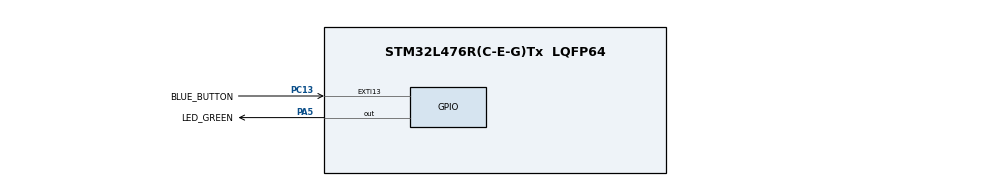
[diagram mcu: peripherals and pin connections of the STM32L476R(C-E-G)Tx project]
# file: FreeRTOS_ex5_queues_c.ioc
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FREERTOS.Queues01=Queue1,8,Data,0,Dynamic,NULL,NULL
FREERTOS.Tasks01=Sender1,24,256,StartSender1,Default,NULL,Dynamic,NULL,NULL;Receive,24,256,StartReceive,Default,NULL,Dynamic,NULL,NULL;Sender2,24,256,StartSender2,Default,NULL,Dynamic,NULL,NULL
FREERTOS.configTOTAL_HEAP_SIZE=4000
FREERTOS.configUSE_NEWLIB_REENTRANT=1
Mcu.Family=STM32L4
Mcu.Name=STM32L476R(C-E-G)Tx
Mcu.Package=LQFP64
NVIC.EXTI15_10_IRQn=true\:5\:0\:true\:false\:true\:false\:true\:true\:true
NVIC.PriorityGroup=NVIC_PRIORITYGROUP_4
NVIC.TIM6_DAC_IRQn=true\:15\:0\:false\:false\:true\:false\:false\:true\:true
NVIC.TimeBase=TIM6_DAC_IRQn
NVIC.TimeBaseIP=TIM6
PA13\ (JTMS-SWDIO).Mode=Trace_Asynchronous_SW
PA13\ (JTMS-SWDIO).Signal=SYS_JTMS-SWDIO
PA14\ (JTCK-SWCLK).Mode=Trace_Asynchronous_SW
PA14\ (JTCK-SWCLK).Signal=SYS_JTCK-SWCLK
PA5.GPIO_Label=LED_GREEN
PA5.Signal=GPIO_Output
PB3\ (JTDO-TRACESWO).Mode=Trace_Asynchronous_SW
PB3\ (JTDO-TRACESWO).Signal=SYS_JTDO-SWO
PC13.GPIO_Label=BLUE_BUTTON
PC13.Signal=GPXTI13
ProjectManager.HeapSize=0x200
ProjectManager.StackSize=0x400
ProjectManager.TargetToolchain=STM32CubeIDE
RCC.HSE_VALUE=8000000
RCC.HSI_VALUE=16000000
RCC.LSE_VALUE=32768
RCC.MSI_VALUE=4000000
RCC.VCOOutputFreq_Value=32000000
VP_FREERTOS_VS_CMSIS_V2.Mode=CMSIS_V2
VP_SYS_VS_tim6.Mode=TIM6
board=custom

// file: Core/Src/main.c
/* USER CODE BEGIN Header */
/**
  ******************************************************************************
  * @file           : main.c
  * @brief          : Main program body
  ******************************************************************************
  * @attention
  *
  * Copyright (c) 2024 STMicroelectronics.
  * All rights reserved.
  *
  * This software is licensed under terms that can be found in the LICENSE file
  * in the root directory of this software component.
  * If no LICENSE file comes with this software, it is provided AS-IS.
  *
  ******************************************************************************
  */
/* USER CODE END Header */
#include "main.h"
#include "cmsis_os.h"

/* USER CODE BEGIN Includes */
#include "stm32l4xx_hal.h"

/* USER CODE END Includes */

/* Definitions for Sender1 */
osThreadId_t Sender1Handle;
const osThreadAttr_t Sender1_attributes = {
  .name = "Sender1",
  .stack_size = 256 * 4,
  .priority = (osPriority_t) osPriorityNormal,
};
/* Definitions for Receive */
osThreadId_t ReceiveHandle;
const osThreadAttr_t Receive_attributes = {
  .name = "Receive",
  .stack_size = 256 * 4,
  .priority = (osPriority_t) osPriorityNormal,
};
/* Definitions for Sender2 */
osThreadId_t Sender2Handle;
const osThreadAttr_t Sender2_attributes = {
  .name = "Sender2",
  .stack_size = 256 * 4,
  .priority = (osPriority_t) osPriorityNormal,
};
/* Definitions for Queue1 */
osMessageQueueId_t Queue1Handle;
const osMessageQueueAttr_t Queue1_attributes = {
  .name = "Queue1"
};
/* USER CODE BEGIN PV */
osStatus_t r_state;
typedef struct
{
	uint16_t value;
	uint8_t source;
} Data;
Data DataToSend1 = {'a', 1};
Data DataToSend2 = {'b', 2};

/* USER CODE END PV */

void SystemClock_Config(void);
static void MX_GPIO_Init(void);
void StartSender1(void *argument);
void StartReceive(void *argument);
void StartSender2(void *argument);

/* USER CODE BEGIN PFP */
void task_action(char message);
/* USER CODE END PFP */

int main(void)
{

  /* MCU Configuration--------------------------------------------------------*/

  /* Reset of all peripherals, Initializes the Flash interface and the Systick. */
  HAL_Init();

  /* Configure the system clock */
  SystemClock_Config();

  /* Initialize all configured peripherals */
  MX_GPIO_Init();

  /* Init scheduler */
  osKernelInitialize();

  /* Create the queue(s) */
  /* creation of Queue1 */
  Queue1Handle = osMessageQueueNew (8, sizeof(Data), &Queue1_attributes);

  /* Create the thread(s) */
  /* creation of Sender1 */
  Sender1Handle = osThreadNew(StartSender1, NULL, &Sender1_attributes);

  /* creation of Receive */
  ReceiveHandle = osThreadNew(StartReceive, NULL, &Receive_attributes);

  /* creation of Sender2 */
  Sender2Handle = osThreadNew(StartSender2, NULL, &Sender2_attributes);

  /* Start scheduler */
  osKernelStart();

  /* We should never get here as control is now taken by the scheduler */
  /* Infinite loop */
  while (1)
  {

  }
}

void SystemClock_Config(void)
{
  RCC_OscInitTypeDef RCC_OscInitStruct = {0};
  RCC_ClkInitTypeDef RCC_ClkInitStruct = {0};

  /** Configure the main internal regulator output voltage
  */
  if (HAL_PWREx_ControlVoltageScaling(PWR_REGULATOR_VOLTAGE_SCALE1) != HAL_OK)
  {
    Error_Handler();
  }

  /** Initializes the RCC Oscillators according to the specified parameters
  * in the RCC_OscInitTypeDef structure.
  */
  RCC_OscInitStruct.OscillatorType = RCC_OSCILLATORTYPE_MSI;
  RCC_OscInitStruct.MSIState = RCC_MSI_ON;
  RCC_OscInitStruct.MSICalibrationValue = 0;
  RCC_OscInitStruct.MSIClockRange = RCC_MSIRANGE_6;
  RCC_OscInitStruct.PLL.PLLState = RCC_PLL_NONE;
  if (HAL_RCC_OscConfig(&RCC_OscInitStruct) != HAL_OK)
  {
    Error_Handler();
  }

  /** Initializes the CPU, AHB and APB buses clocks
  */
  RCC_ClkInitStruct.ClockType = RCC_CLOCKTYPE_HCLK|RCC_CLOCKTYPE_SYSCLK
                              |RCC_CLOCKTYPE_PCLK1|RCC_CLOCKTYPE_PCLK2;
  RCC_ClkInitStruct.SYSCLKSource = RCC_SYSCLKSOURCE_MSI;
  RCC_ClkInitStruct.AHBCLKDivider = RCC_SYSCLK_DIV1;
  RCC_ClkInitStruct.APB1CLKDivider = RCC_HCLK_DIV1;
  RCC_ClkInitStruct.APB2CLKDivider = RCC_HCLK_DIV1;

  if (HAL_RCC_ClockConfig(&RCC_ClkInitStruct, FLASH_LATENCY_0) != HAL_OK)
  {
    Error_Handler();
  }
}

static void MX_GPIO_Init(void)
{
  GPIO_InitTypeDef GPIO_InitStruct = {0};

  /* GPIO Ports Clock Enable */
  __HAL_RCC_GPIOC_CLK_ENABLE();
  __HAL_RCC_GPIOA_CLK_ENABLE();
  __HAL_RCC_GPIOB_CLK_ENABLE();

  /*Configure GPIO pin Output Level */
  HAL_GPIO_WritePin(LED_GREEN_GPIO_Port, LED_GREEN_Pin, GPIO_PIN_RESET);

  /*Configure GPIO pin : BLUE_BUTTON_Pin */
  GPIO_InitStruct.Pin = BLUE_BUTTON_Pin;
  GPIO_InitStruct.Mode = GPIO_MODE_IT_RISING;
  GPIO_InitStruct.Pull = GPIO_NOPULL;
  HAL_GPIO_Init(BLUE_BUTTON_GPIO_Port, &GPIO_InitStruct);

  /*Configure GPIO pin : LED_GREEN_Pin */
  GPIO_InitStruct.Pin = LED_GREEN_Pin;
  GPIO_InitStruct.Mode = GPIO_MODE_OUTPUT_PP;
  GPIO_InitStruct.Pull = GPIO_NOPULL;
  GPIO_InitStruct.Speed = GPIO_SPEED_FREQ_LOW;
  HAL_GPIO_Init(LED_GREEN_GPIO_Port, &GPIO_InitStruct);

  /* EXTI interrupt init*/
  HAL_NVIC_SetPriority(EXTI15_10_IRQn, 5, 0);
  HAL_NVIC_EnableIRQ(EXTI15_10_IRQn);

}

/* USER CODE BEGIN 4 */
void task_action(char message)
{
	ITM_SendChar(message);
	ITM_SendChar('\n');
}

/* USER CODE END 4 */

void StartSender1(void *argument)
{
  /* USER CODE BEGIN 5 */

  /* Infinite loop */
  for(;;)
  {
	//HAL_GPIO_TogglePin(LED_GREEN_GPIO_Port, LED_GREEN_Pin);
	for(;;)
	{
	  task_action('s');
	  r_state = osMessageQueuePut(Queue1Handle, &DataToSend1, 0, 200);
	  osDelay(2000);
	}
  }
  /* USER CODE END 5 */
}

void StartReceive(void *argument)
{
  /* USER CODE BEGIN StartReceive */
  Data retvalue;

  /* Infinite loop */
  for(;;)
  {
	task_action('R');
	r_state = osMessageQueueGet(Queue1Handle, &retvalue, NULL, osWaitForever);
	if(retvalue.source == 1)
	{
		HAL_GPIO_WritePin(LED_GREEN_GPIO_Port, LED_GREEN_Pin, GPIO_PIN_SET);
	}
	else
	{
		HAL_GPIO_WritePin(LED_GREEN_GPIO_Port, LED_GREEN_Pin, GPIO_PIN_RESET);
	}
	task_action(retvalue.value);

//	osDelay(2000);//This interval will cause the Queue to Overflow
//	osDelay(1000); //This interval is required to avoid Queue overflow
  }
  /* USER CODE END StartReceive */
}

void StartSender2(void *argument)
{
  /* USER CODE BEGIN StartSender2 */

  /* Infinite loop */
  for(;;)
  {
	task_action('S');
	r_state = osMessageQueuePut(Queue1Handle, &DataToSend2, 0, 200);
    osDelay(2000);
  }
  /* USER CODE END StartSender2 */
}

void HAL_TIM_PeriodElapsedCallback(TIM_HandleTypeDef *htim)
{
  if (htim->Instance == TIM6) {
    HAL_IncTick();
  }
}

void Error_Handler(void)
{
  __disable_irq();
  while (1)
  {
  }
}
